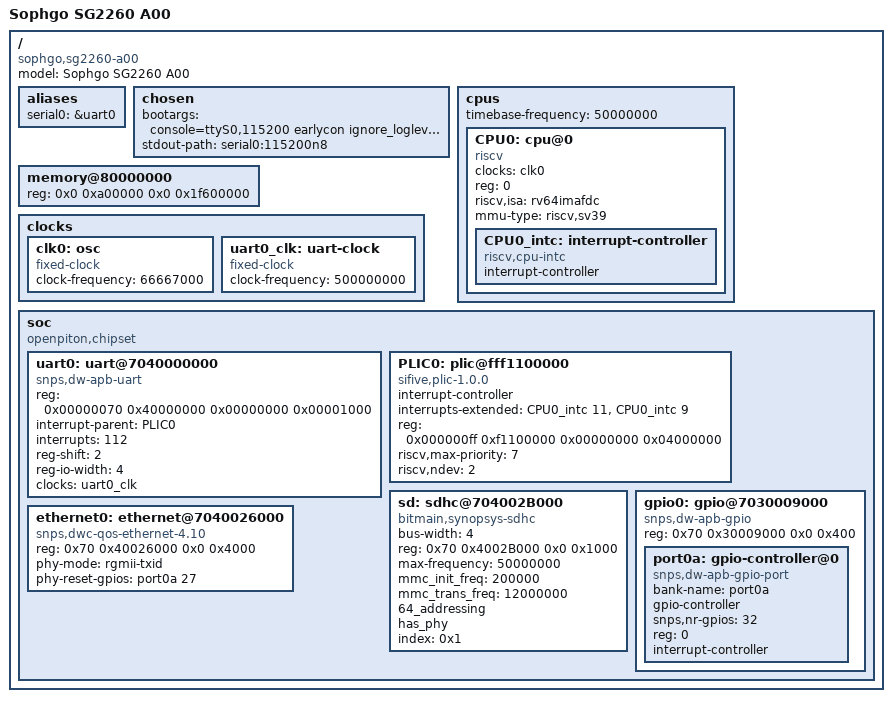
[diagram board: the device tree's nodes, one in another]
// SPDX-License-Identifier: GPL-2.0+
/*
 * Copyright (C) 2023 Yixun Lan <dlan@gentoo.org>
 */

/dts-v1/;

/ {
	model = "Sophgo SG2260 A00";
	compatible = "sophgo,sg2260-a00";
	#address-cells = <2>;
	#size-cells = <2>;

	aliases {
		serial0 = &uart0;
	};

	chosen {
		bootargs = "console=ttyS0,115200 earlycon ignore_loglevel rdinit=/init root=/dev/ram0 rw initrd=0x90000000,32M retain_initrd maxcpus=1 nvme.use_threaded_interrupts=1 nvme_core.io_timeout=3000";
		stdout-path = "serial0:115200n8";
	};

	cpus {
		#address-cells = <1>;
		#size-cells = <0>;
		timebase-frequency = <50000000>;

		CPU0: cpu@0 {
			clocks = <&clk0>;
			device_type = "cpu";
			reg = <0>;
			compatible = "riscv";
			riscv,isa = "rv64imafdc";
			mmu-type = "riscv,sv39";
			// HLIC - hart local interrupt controller
			CPU0_intc: interrupt-controller {
				#interrupt-cells = <1>;
				interrupt-controller;
				compatible = "riscv,cpu-intc";
			};
		};
	};

	memory@80000000 {
		device_type = "memory";
		reg = <0x0 0xa00000 0x0 0x1f600000>;
	};

	clocks {
		clk0: osc {
			compatible = "fixed-clock";
			#clock-cells = <0>;
			clock-frequency = <66667000>;
		};

		uart0_clk: uart-clock {
			compatible = "fixed-clock";
			#clock-cells = <0>;
			clock-frequency = <500000000>;
		};
	};

	soc {
		#address-cells = <2>;
		#size-cells = <2>;
		compatible = "openpiton,chipset", "simple-bus";
		ranges;

		uart0: uart@7040000000 {
			compatible = "snps,dw-apb-uart";
			reg = <0x00000070 0x40000000 0x00000000 0x00001000>;
			interrupt-parent = <&PLIC0>;
			interrupts = <112>;
			reg-shift = <2>;
			reg-io-width = <4>;
			clocks = <&uart0_clk>;
			status = "okay";
		};

		PLIC0: plic@fff1100000 {
			#interrupt-cells = <1>;
			compatible = "sifive,plic-1.0.0";
			interrupt-controller;
			interrupts-extended = < &CPU0_intc 11
						&CPU0_intc 9 >;
			reg = < 0x000000ff 0xf1100000 0x00000000 0x04000000 >;
			riscv,max-priority = <7>;
			riscv,ndev = <2>;
		};

		sd: sdhc@704002B000 {
			compatible = "bitmain,synopsys-sdhc";
			bus-width = <4>;
			reg = <0x70 0x4002B000 0x0 0x1000>;
			max-frequency = <50000000>;
			mmc_init_freq = <200000>;
			mmc_trans_freq = <12000000>;
			64_addressing;
			has_phy;
			index = <0x1>;
			status = "okay";
		};

		gpio0: gpio@7030009000 {
			compatible = "snps,dw-apb-gpio";
			reg = <0x70 0x30009000 0x0 0x400>;
			#address-cells = <1>;
			#size-cells = <0>;

			port0a: gpio-controller@0 {
				compatible = "snps,dw-apb-gpio-port";
				bank-name = "port0a";
				gpio-controller;
				#gpio-cells = <2>;
				snps,nr-gpios = <32>;
				reg = <0>;
				interrupt-controller;
				#interrupt-cells = <2>;
			};
		};

		ethernet0: ethernet@7040026000 {
			compatible = "snps,dwc-qos-ethernet-4.10";
			reg = <0x70 0x40026000  0x0 0x4000>;
			reg-names = "mac";
			phy-mode = "rgmii-txid";
			phy-reset-gpios = <&port0a 27 0>;
		};
	};
};
